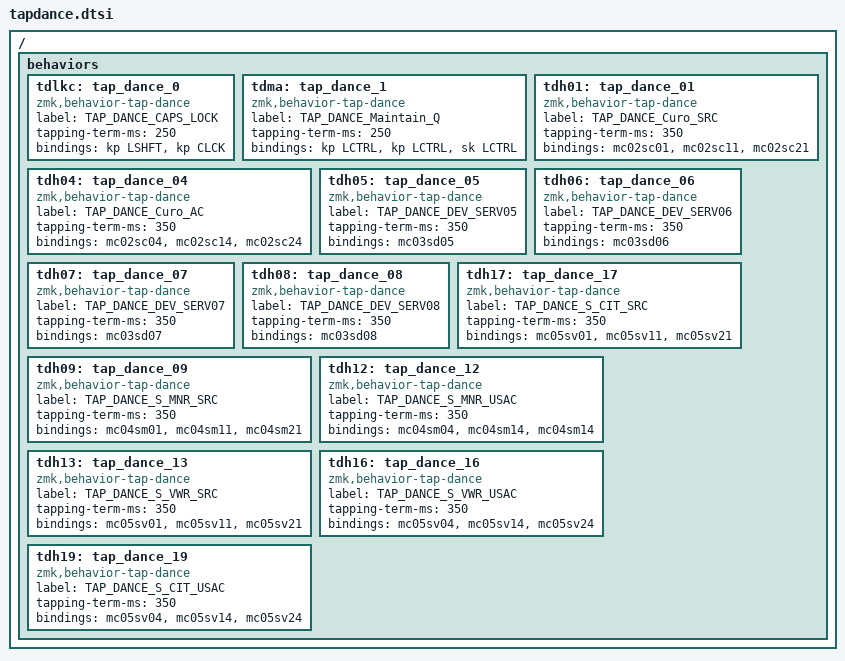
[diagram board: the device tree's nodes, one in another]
/ {

    behaviors {
        tdlkc: tap_dance_0 {
            compatible = "zmk,behavior-tap-dance";
            label = "TAP_DANCE_CAPS_LOCK";
            #binding-cells = <0>;
            tapping-term-ms = <250>;
            bindings = <&kp LSHFT>, <&kp CLCK>;
        };
        tdma: tap_dance_1 {
            compatible = "zmk,behavior-tap-dance";
            label = "TAP_DANCE_Maintain_Q";
            #binding-cells = <0>;
            tapping-term-ms = <250>;
            bindings = <&kp LCTRL>, <&kp LCTRL>, <&sk LCTRL> ;
        };

        /*********************
        Tap Dance to open Curo
        *********************/
        tdh01: tap_dance_01 {
            compatible = "zmk,behavior-tap-dance";
            label = "TAP_DANCE_Curo_SRC";
            #binding-cells = <0>;
            tapping-term-ms = <350>;
            bindings = <&mc02sc01>, <&mc02sc11>, <&mc02sc21>;
        };

        tdh04: tap_dance_04 {
            compatible = "zmk,behavior-tap-dance";
            label = "TAP_DANCE_Curo_AC";
            #binding-cells = <0>;
            tapping-term-ms = <350>;
            bindings = <&mc02sc04>, <&mc02sc14>, <&mc02sc24>;
        };

        /****************************
        Tap Dance to open Dev Servers
        *****************************/
        tdh05: tap_dance_05 {
            compatible = "zmk,behavior-tap-dance";
            label = "TAP_DANCE_DEV_SERV05";
            #binding-cells = <0>;
            tapping-term-ms = <350>;
            bindings = <&mc03sd05>;
        };

        tdh06: tap_dance_06 {
            compatible = "zmk,behavior-tap-dance";
            label = "TAP_DANCE_DEV_SERV06";
            #binding-cells = <0>;
            tapping-term-ms = <350>;
            bindings = <&mc03sd06>;
        };

        tdh07: tap_dance_07 {
            compatible = "zmk,behavior-tap-dance";
            label = "TAP_DANCE_DEV_SERV07";
            #binding-cells = <0>;
            tapping-term-ms = <350>;
            bindings = <&mc03sd07>;
        };

        tdh08: tap_dance_08 {
            compatible = "zmk,behavior-tap-dance";
            label = "TAP_DANCE_DEV_SERV08";
            #binding-cells = <0>;
            tapping-term-ms = <350>;
            bindings = <&mc03sd08>;
        };

        tdh17: tap_dance_17 {
            compatible = "zmk,behavior-tap-dance";
            label = "TAP_DANCE_CURIA_SERV07";
            #binding-cells = <0>;
            tapping-term-ms = <350>;
            bindings = <&mc03sv07>, <&mc03sv08>;
        };

        /********************************
        Tap Dance to open Scoring Manager
        ********************************/
        tdh09: tap_dance_09 {
            compatible = "zmk,behavior-tap-dance";
            label = "TAP_DANCE_S_MNR_SRC";
            #binding-cells = <0>;
            tapping-term-ms = <350>;
            bindings = <&mc04sm01>, <&mc04sm11>, <&mc04sm21>;
        };

        tdh12: tap_dance_12 {
            compatible = "zmk,behavior-tap-dance";
            label = "TAP_DANCE_S_MNR_USAC";
            #binding-cells = <0>;
            tapping-term-ms = <350>;
            bindings = <&mc04sm04>, <&mc04sm14>, <&mc04sm14>;
        };

        /*******************************
        Tap Dance to open Scoring Viewer
        *******************************/
        tdh13: tap_dance_13 {
            compatible = "zmk,behavior-tap-dance";
            label = "TAP_DANCE_S_VWR_SRC";
            #binding-cells = <0>;
            tapping-term-ms = <350>;
            bindings = <&mc05sv01>, <&mc05sv11>, <&mc05sv21>;
        };

        tdh16: tap_dance_16 {
            compatible = "zmk,behavior-tap-dance";
            label = "TAP_DANCE_S_VWR_USAC";
            #binding-cells = <0>;
            tapping-term-ms = <350>;
            bindings = <&mc05sv04>, <&mc05sv14>, <&mc05sv24>;
        };

        
        /*******************************
        Tap Dance to open Cito
        *******************************/
        tdh17: tap_dance_17 {
            compatible = "zmk,behavior-tap-dance";
            label = "TAP_DANCE_S_CIT_SRC";
            #binding-cells = <0>;
            tapping-term-ms = <350>;
            bindings = <&mc05sv01>, <&mc05sv11>, <&mc05sv21>;
        };

        tdh19: tap_dance_19 {
            compatible = "zmk,behavior-tap-dance";
            label = "TAP_DANCE_S_CIT_USAC";
            #binding-cells = <0>;
            tapping-term-ms = <350>;
            bindings = <&mc05sv04>, <&mc05sv14>, <&mc05sv24>;
        };
    };
};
